# MSS_CTRL_MSS_CTRL register map
Vendor: Texas Instruments
Registers are 32-bit, read-only, reset 0x0 unless marked. A register's access mark holds for its fields unless they carry their own. Offsets are as the file gives them; [hi:lo] are bit positions; 'fields as' and 'values as' point back to an identical list.

## MSS_CTRL_MSS_CTRL (part 4 of 5)
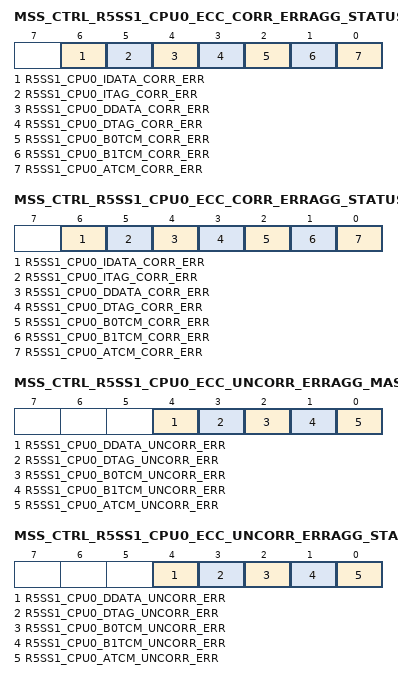
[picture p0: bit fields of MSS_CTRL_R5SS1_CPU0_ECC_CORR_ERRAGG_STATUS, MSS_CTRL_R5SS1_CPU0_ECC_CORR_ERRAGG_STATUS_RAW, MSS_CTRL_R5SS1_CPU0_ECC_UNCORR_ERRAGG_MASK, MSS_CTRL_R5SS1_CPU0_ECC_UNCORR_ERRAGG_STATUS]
0x180C4 MSS_CTRL_R5SS1_CPU0_ECC_CORR_ERRAGG_STATUS 8-bit rw
  [6] R5SS1_CPU0_IDATA_CORR_ERR — Status of Interrupt from correctable error of corresponding CPUSet only if Interupt is unmasked in corresponding R5SS*_CPU*_ECC_CORR_ERRAGG_MASK registerWrie 0x1 to clear this interrupt.
  [5] R5SS1_CPU0_ITAG_CORR_ERR — Status of Interrupt from correctable error of corresponding CPUSet only if Interupt is unmasked in corresponding R5SS*_CPU*_ECC_CORR_ERRAGG_MASK registerWrie 0x1 to clear this interrupt.
  [4] R5SS1_CPU0_DDATA_CORR_ERR — Status of Interrupt from correctable error of corresponding CPUSet only if Interupt is unmasked in corresponding R5SS*_CPU*_ECC_CORR_ERRAGG_MASK registerWrie 0x1 to clear this interrupt.
  [3] R5SS1_CPU0_DTAG_CORR_ERR — Status of Interrupt from correctable error of corresponding CPUSet only if Interupt is unmasked in corresponding R5SS*_CPU*_ECC_CORR_ERRAGG_MASK registerWrie 0x1 to clear this interrupt.
  [2] R5SS1_CPU0_B0TCM_CORR_ERR — Status of Interrupt from correctable error of corresponding CPUSet only if Interupt is unmasked in corresponding R5SS*_CPU*_ECC_CORR_ERRAGG_MASK registerWrie 0x1 to clear this interrupt.
  [1] R5SS1_CPU0_B1TCM_CORR_ERR — Status of Interrupt from correctable error of corresponding CPUSet only if Interupt is unmasked in corresponding R5SS*_CPU*_ECC_CORR_ERRAGG_MASK registerWrie 0x1 to clear this interrupt.
  [0] R5SS1_CPU0_ATCM_CORR_ERR — Status of Interrupt from correctable error of corresponding CPUSet only if Interupt is unmasked in corresponding R5SS*_CPU*_ECC_CORR_ERRAGG_MASK registerWrie 0x1 to clear this interrupt.
0x180C8 MSS_CTRL_R5SS1_CPU0_ECC_CORR_ERRAGG_STATUS_RAW 8-bit rw
  [6] R5SS1_CPU0_IDATA_CORR_ERR — Raw Status of Interrupt from correctable error of corresponding CPUSet only if Interupt is unmasked in corresponding R5SS*_CPU*_ECC_CORR_ERRAGG_MASK registerWrie 0x1 to clear this interrupt.
  [5] R5SS1_CPU0_ITAG_CORR_ERR — Raw Status of Interrupt from correctable error of corresponding CPUSet only if Interupt is unmasked in corresponding R5SS*_CPU*_ECC_CORR_ERRAGG_MASK registerWrie 0x1 to clear this interrupt.
  [4] R5SS1_CPU0_DDATA_CORR_ERR — Raw Status of Interrupt from correctable error of corresponding CPUSet only if Interupt is unmasked in corresponding R5SS*_CPU*_ECC_CORR_ERRAGG_MASK registerWrie 0x1 to clear this interrupt.
  [3] R5SS1_CPU0_DTAG_CORR_ERR — Raw Status of Interrupt from correctable error of corresponding CPUSet only if Interupt is unmasked in corresponding R5SS*_CPU*_ECC_CORR_ERRAGG_MASK registerWrie 0x1 to clear this interrupt.
  [2] R5SS1_CPU0_B0TCM_CORR_ERR — Raw Status of Interrupt from correctable error of corresponding CPUSet only if Interupt is unmasked in corresponding R5SS*_CPU*_ECC_CORR_ERRAGG_MASK registerWrie 0x1 to clear this interrupt.
  [1] R5SS1_CPU0_B1TCM_CORR_ERR — Raw Status of Interrupt from correctable error of corresponding CPUSet only if Interupt is unmasked in corresponding R5SS*_CPU*_ECC_CORR_ERRAGG_MASK registerWrie 0x1 to clear this interrupt.
  [0] R5SS1_CPU0_ATCM_CORR_ERR — Raw Status of Interrupt from correctable error of corresponding CPUSet only if Interupt is unmasked in corresponding R5SS*_CPU*_ECC_CORR_ERRAGG_MASK registerWrie 0x1 to clear this interrupt.
0x180D0 MSS_CTRL_R5SS1_CPU0_ECC_UNCORR_ERRAGG_MASK 8-bit rw
  [4] R5SS1_CPU0_DDATA_UNCORR_ERR — Mask Interrupt for correctable errors to aggregated Interrupt of corresponding CPU1 : Interrupt is Masked0 : Interrupt is Unmasked
  [3] R5SS1_CPU0_DTAG_UNCORR_ERR — Mask Interrupt for correctable errors to aggregated Interrupt of corresponding CPU1 : Interrupt is Masked0 : Interrupt is Unmasked
  [2] R5SS1_CPU0_B0TCM_UNCORR_ERR — Mask Interrupt for correctable errors to aggregated Interrupt of corresponding CPU1 : Interrupt is Masked0 : Interrupt is Unmasked
  [1] R5SS1_CPU0_B1TCM_UNCORR_ERR — Mask Interrupt for correctable errors to aggregated Interrupt of corresponding CPU1 : Interrupt is Masked0 : Interrupt is Unmasked
  [0] R5SS1_CPU0_ATCM_UNCORR_ERR — Mask Interrupt for correctable errors to aggregated Interrupt of corresponding CPU1 : Interrupt is Masked0 : Interrupt is Unmasked
0x180D4 MSS_CTRL_R5SS1_CPU0_ECC_UNCORR_ERRAGG_STATUS 8-bit rw
  [4] R5SS1_CPU0_DDATA_UNCORR_ERR — Status of Interrupt from correctable error of corresponding CPUSet only if Interupt is unmasked in corresponding R5SS*_CPU*_ECC_UNCORR_ERRAGG_MASK registerWrie 0x1 to clear this interrupt.
  [3] R5SS1_CPU0_DTAG_UNCORR_ERR — Status of Interrupt from correctable error of corresponding CPUSet only if Interupt is unmasked in corresponding R5SS*_CPU*_ECC_UNCORR_ERRAGG_MASK registerWrie 0x1 to clear this interrupt.
  [2] R5SS1_CPU0_B0TCM_UNCORR_ERR — Status of Interrupt from correctable error of corresponding CPUSet only if Interupt is unmasked in corresponding R5SS*_CPU*_ECC_UNCORR_ERRAGG_MASK registerWrie 0x1 to clear this interrupt.
  [1] R5SS1_CPU0_B1TCM_UNCORR_ERR — Status of Interrupt from correctable error of corresponding CPUSet only if Interupt is unmasked in corresponding R5SS*_CPU*_ECC_UNCORR_ERRAGG_MASK registerWrie 0x1 to clear this interrupt.
  [0] R5SS1_CPU0_ATCM_UNCORR_ERR — Status of Interrupt from correctable error of corresponding CPUSet only if Interupt is unmasked in corresponding R5SS*_CPU*_ECC_UNCORR_ERRAGG_MASK registerWrie 0x1 to clear this interrupt.
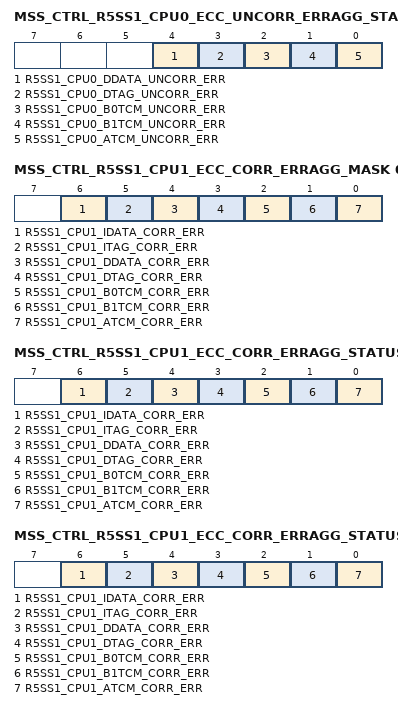
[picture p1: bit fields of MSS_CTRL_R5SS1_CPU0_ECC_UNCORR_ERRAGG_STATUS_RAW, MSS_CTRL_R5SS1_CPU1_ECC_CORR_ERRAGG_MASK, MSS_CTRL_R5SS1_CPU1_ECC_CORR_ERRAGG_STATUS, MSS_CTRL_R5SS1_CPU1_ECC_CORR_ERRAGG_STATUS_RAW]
0x180D8 MSS_CTRL_R5SS1_CPU0_ECC_UNCORR_ERRAGG_STATUS_RAW 8-bit rw
  [4] R5SS1_CPU0_DDATA_UNCORR_ERR — Raw Status of Interrupt from correctable error of corresponding CPUSet only if Interupt is unmasked in corresponding R5SS*_CPU*_ECC_UNCORR_ERRAGG_MASK registerWrie 0x1 to clear this interrupt.
  [3] R5SS1_CPU0_DTAG_UNCORR_ERR — Raw Status of Interrupt from correctable error of corresponding CPUSet only if Interupt is unmasked in corresponding R5SS*_CPU*_ECC_UNCORR_ERRAGG_MASK registerWrie 0x1 to clear this interrupt.
  [2] R5SS1_CPU0_B0TCM_UNCORR_ERR — Raw Status of Interrupt from correctable error of corresponding CPUSet only if Interupt is unmasked in corresponding R5SS*_CPU*_ECC_UNCORR_ERRAGG_MASK registerWrie 0x1 to clear this interrupt.
  [1] R5SS1_CPU0_B1TCM_UNCORR_ERR — Raw Status of Interrupt from correctable error of corresponding CPUSet only if Interupt is unmasked in corresponding R5SS*_CPU*_ECC_UNCORR_ERRAGG_MASK registerWrie 0x1 to clear this interrupt.
  [0] R5SS1_CPU0_ATCM_UNCORR_ERR — Raw Status of Interrupt from correctable error of corresponding CPUSet only if Interupt is unmasked in corresponding R5SS*_CPU*_ECC_UNCORR_ERRAGG_MASK registerWrie 0x1 to clear this interrupt.
0x180E0 MSS_CTRL_R5SS1_CPU1_ECC_CORR_ERRAGG_MASK 8-bit rw
  [6] R5SS1_CPU1_IDATA_CORR_ERR — Mask Interrupt for correctable errors to aggregated Interrupt of corresponding CPU1 : Interrupt is Masked0 : Interrupt is Unmasked
  [5] R5SS1_CPU1_ITAG_CORR_ERR — Mask Interrupt for correctable errors to aggregated Interrupt of corresponding CPU1 : Interrupt is Masked0 : Interrupt is Unmasked
  [4] R5SS1_CPU1_DDATA_CORR_ERR — Mask Interrupt for correctable errors to aggregated Interrupt of corresponding CPU1 : Interrupt is Masked0 : Interrupt is Unmasked
  [3] R5SS1_CPU1_DTAG_CORR_ERR — Mask Interrupt for correctable errors to aggregated Interrupt of corresponding CPU1 : Interrupt is Masked0 : Interrupt is Unmasked
  [2] R5SS1_CPU1_B0TCM_CORR_ERR — Mask Interrupt for correctable errors to aggregated Interrupt of corresponding CPU1 : Interrupt is Masked0 : Interrupt is Unmasked
  [1] R5SS1_CPU1_B1TCM_CORR_ERR — Mask Interrupt for correctable errors to aggregated Interrupt of corresponding CPU1 : Interrupt is Masked0 : Interrupt is Unmasked
  [0] R5SS1_CPU1_ATCM_CORR_ERR — Mask Interrupt for correctable errors to aggregated Interrupt of corresponding CPU1 : Interrupt is Masked0 : Interrupt is Unmasked
0x180E4 MSS_CTRL_R5SS1_CPU1_ECC_CORR_ERRAGG_STATUS 8-bit rw
  [6] R5SS1_CPU1_IDATA_CORR_ERR — Status of Interrupt from correctable error of corresponding CPUSet only if Interupt is unmasked in corresponding R5SS*_CPU*_ECC_CORR_ERRAGG_MASK registerWrie 0x1 to clear this interrupt.
  [5] R5SS1_CPU1_ITAG_CORR_ERR — Status of Interrupt from correctable error of corresponding CPUSet only if Interupt is unmasked in corresponding R5SS*_CPU*_ECC_CORR_ERRAGG_MASK registerWrie 0x1 to clear this interrupt.
  [4] R5SS1_CPU1_DDATA_CORR_ERR — Status of Interrupt from correctable error of corresponding CPUSet only if Interupt is unmasked in corresponding R5SS*_CPU*_ECC_CORR_ERRAGG_MASK registerWrie 0x1 to clear this interrupt.
  [3] R5SS1_CPU1_DTAG_CORR_ERR — Status of Interrupt from correctable error of corresponding CPUSet only if Interupt is unmasked in corresponding R5SS*_CPU*_ECC_CORR_ERRAGG_MASK registerWrie 0x1 to clear this interrupt.
  [2] R5SS1_CPU1_B0TCM_CORR_ERR — Status of Interrupt from correctable error of corresponding CPUSet only if Interupt is unmasked in corresponding R5SS*_CPU*_ECC_CORR_ERRAGG_MASK registerWrie 0x1 to clear this interrupt.
  [1] R5SS1_CPU1_B1TCM_CORR_ERR — Status of Interrupt from correctable error of corresponding CPUSet only if Interupt is unmasked in corresponding R5SS*_CPU*_ECC_CORR_ERRAGG_MASK registerWrie 0x1 to clear this interrupt.
  [0] R5SS1_CPU1_ATCM_CORR_ERR — Status of Interrupt from correctable error of corresponding CPUSet only if Interupt is unmasked in corresponding R5SS*_CPU*_ECC_CORR_ERRAGG_MASK registerWrie 0x1 to clear this interrupt.
0x180E8 MSS_CTRL_R5SS1_CPU1_ECC_CORR_ERRAGG_STATUS_RAW 8-bit rw
  [6] R5SS1_CPU1_IDATA_CORR_ERR — Raw Status of Interrupt from correctable error of corresponding CPUSet only if Interupt is unmasked in corresponding R5SS*_CPU*_ECC_CORR_ERRAGG_MASK registerWrie 0x1 to clear this interrupt.
  [5] R5SS1_CPU1_ITAG_CORR_ERR — Raw Status of Interrupt from correctable error of corresponding CPUSet only if Interupt is unmasked in corresponding R5SS*_CPU*_ECC_CORR_ERRAGG_MASK registerWrie 0x1 to clear this interrupt.
  [4] R5SS1_CPU1_DDATA_CORR_ERR — Raw Status of Interrupt from correctable error of corresponding CPUSet only if Interupt is unmasked in corresponding R5SS*_CPU*_ECC_CORR_ERRAGG_MASK registerWrie 0x1 to clear this interrupt.
  [3] R5SS1_CPU1_DTAG_CORR_ERR — Raw Status of Interrupt from correctable error of corresponding CPUSet only if Interupt is unmasked in corresponding R5SS*_CPU*_ECC_CORR_ERRAGG_MASK registerWrie 0x1 to clear this interrupt.
  [2] R5SS1_CPU1_B0TCM_CORR_ERR — Raw Status of Interrupt from correctable error of corresponding CPUSet only if Interupt is unmasked in corresponding R5SS*_CPU*_ECC_CORR_ERRAGG_MASK registerWrie 0x1 to clear this interrupt.
  [1] R5SS1_CPU1_B1TCM_CORR_ERR — Raw Status of Interrupt from correctable error of corresponding CPUSet only if Interupt is unmasked in corresponding R5SS*_CPU*_ECC_CORR_ERRAGG_MASK registerWrie 0x1 to clear this interrupt.
  [0] R5SS1_CPU1_ATCM_CORR_ERR — Raw Status of Interrupt from correctable error of corresponding CPUSet only if Interupt is unmasked in corresponding R5SS*_CPU*_ECC_CORR_ERRAGG_MASK registerWrie 0x1 to clear this interrupt.
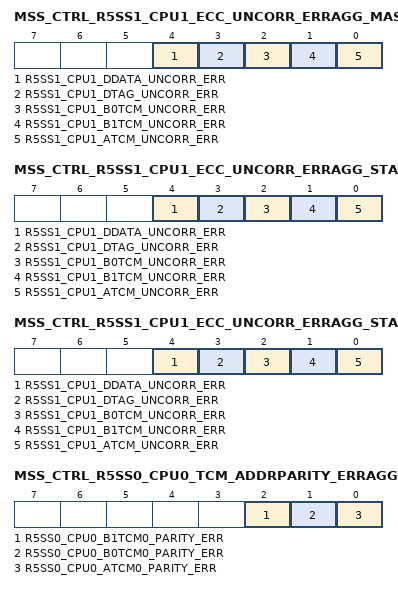
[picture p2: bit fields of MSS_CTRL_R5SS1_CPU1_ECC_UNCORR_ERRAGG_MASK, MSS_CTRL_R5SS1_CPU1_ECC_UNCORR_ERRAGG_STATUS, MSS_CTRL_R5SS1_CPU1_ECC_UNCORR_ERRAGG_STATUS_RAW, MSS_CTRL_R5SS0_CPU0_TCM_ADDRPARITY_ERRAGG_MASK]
0x180F0 MSS_CTRL_R5SS1_CPU1_ECC_UNCORR_ERRAGG_MASK 8-bit rw
  [4] R5SS1_CPU1_DDATA_UNCORR_ERR — Mask Interrupt for correctable errors to aggregated Interrupt of corresponding CPU1 : Interrupt is Masked0 : Interrupt is Unmasked
  [3] R5SS1_CPU1_DTAG_UNCORR_ERR — Mask Interrupt for correctable errors to aggregated Interrupt of corresponding CPU1 : Interrupt is Masked0 : Interrupt is Unmasked
  [2] R5SS1_CPU1_B0TCM_UNCORR_ERR — Mask Interrupt for correctable errors to aggregated Interrupt of corresponding CPU1 : Interrupt is Masked0 : Interrupt is Unmasked
  [1] R5SS1_CPU1_B1TCM_UNCORR_ERR — Mask Interrupt for correctable errors to aggregated Interrupt of corresponding CPU1 : Interrupt is Masked0 : Interrupt is Unmasked
  [0] R5SS1_CPU1_ATCM_UNCORR_ERR — Mask Interrupt for correctable errors to aggregated Interrupt of corresponding CPU1 : Interrupt is Masked0 : Interrupt is Unmasked
0x180F4 MSS_CTRL_R5SS1_CPU1_ECC_UNCORR_ERRAGG_STATUS 8-bit rw
  [4] R5SS1_CPU1_DDATA_UNCORR_ERR — Status of Interrupt from correctable error of corresponding CPUSet only if Interupt is unmasked in corresponding R5SS*_CPU*_ECC_UNCORR_ERRAGG_MASK registerWrie 0x1 to clear this interrupt.
  [3] R5SS1_CPU1_DTAG_UNCORR_ERR — Status of Interrupt from correctable error of corresponding CPUSet only if Interupt is unmasked in corresponding R5SS*_CPU*_ECC_UNCORR_ERRAGG_MASK registerWrie 0x1 to clear this interrupt.
  [2] R5SS1_CPU1_B0TCM_UNCORR_ERR — Status of Interrupt from correctable error of corresponding CPUSet only if Interupt is unmasked in corresponding R5SS*_CPU*_ECC_UNCORR_ERRAGG_MASK registerWrie 0x1 to clear this interrupt.
  [1] R5SS1_CPU1_B1TCM_UNCORR_ERR — Status of Interrupt from correctable error of corresponding CPUSet only if Interupt is unmasked in corresponding R5SS*_CPU*_ECC_UNCORR_ERRAGG_MASK registerWrie 0x1 to clear this interrupt.
  [0] R5SS1_CPU1_ATCM_UNCORR_ERR — Status of Interrupt from correctable error of corresponding CPUSet only if Interupt is unmasked in corresponding R5SS*_CPU*_ECC_UNCORR_ERRAGG_MASK registerWrie 0x1 to clear this interrupt.
0x180F8 MSS_CTRL_R5SS1_CPU1_ECC_UNCORR_ERRAGG_STATUS_RAW 8-bit rw
  [4] R5SS1_CPU1_DDATA_UNCORR_ERR — Raw Status of Interrupt from correctable error of corresponding CPUSet only if Interupt is unmasked in corresponding R5SS*_CPU*_ECC_UNCORR_ERRAGG_MASK registerWrie 0x1 to clear this interrupt.
  [3] R5SS1_CPU1_DTAG_UNCORR_ERR — Raw Status of Interrupt from correctable error of corresponding CPUSet only if Interupt is unmasked in corresponding R5SS*_CPU*_ECC_UNCORR_ERRAGG_MASK registerWrie 0x1 to clear this interrupt.
  [2] R5SS1_CPU1_B0TCM_UNCORR_ERR — Raw Status of Interrupt from correctable error of corresponding CPUSet only if Interupt is unmasked in corresponding R5SS*_CPU*_ECC_UNCORR_ERRAGG_MASK registerWrie 0x1 to clear this interrupt.
  [1] R5SS1_CPU1_B1TCM_UNCORR_ERR — Raw Status of Interrupt from correctable error of corresponding CPUSet only if Interupt is unmasked in corresponding R5SS*_CPU*_ECC_UNCORR_ERRAGG_MASK registerWrie 0x1 to clear this interrupt.
  [0] R5SS1_CPU1_ATCM_UNCORR_ERR — Raw Status of Interrupt from correctable error of corresponding CPUSet only if Interupt is unmasked in corresponding R5SS*_CPU*_ECC_UNCORR_ERRAGG_MASK registerWrie 0x1 to clear this interrupt.
0x18100 MSS_CTRL_R5SS0_CPU0_TCM_ADDRPARITY_ERRAGG_MASK 8-bit rw
  [2] R5SS0_CPU0_B1TCM0_PARITY_ERR — Mask Interrupt for address parity error s to aggregated Interrupt of corresponding CPU1 : Interrupt is Masked0 : Interrupt is Unmasked
  [1] R5SS0_CPU0_B0TCM0_PARITY_ERR — Mask Interrupt for address parity error s to aggregated Interrupt of corresponding CPU1 : Interrupt is Masked0 : Interrupt is Unmasked
  [0] R5SS0_CPU0_ATCM0_PARITY_ERR — Mask Interrupt for address parity error s to aggregated Interrupt of corresponding CPU1 : Interrupt is Masked0 : Interrupt is Unmasked
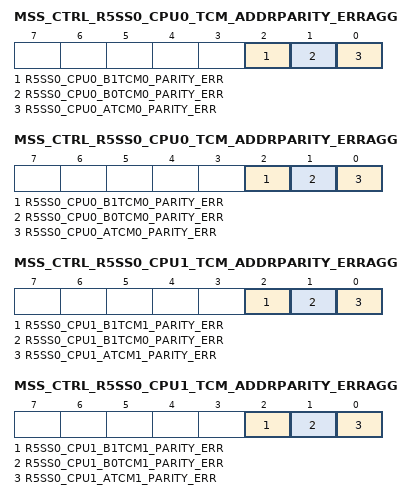
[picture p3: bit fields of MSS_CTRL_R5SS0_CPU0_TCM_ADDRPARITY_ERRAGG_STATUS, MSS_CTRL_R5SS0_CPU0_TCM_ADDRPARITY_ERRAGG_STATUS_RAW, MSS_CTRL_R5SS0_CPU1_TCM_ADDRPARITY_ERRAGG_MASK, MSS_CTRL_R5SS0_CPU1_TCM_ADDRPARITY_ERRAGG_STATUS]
0x18104 MSS_CTRL_R5SS0_CPU0_TCM_ADDRPARITY_ERRAGG_STATUS 8-bit rw
  [2] R5SS0_CPU0_B1TCM0_PARITY_ERR — Status of Interrupt from address parity error of corresponding CPU*_TCM_ADDRPARITY_ERRAGG_MASK registerWrie 0x1 to clear this interrupt.
  [1] R5SS0_CPU0_B0TCM0_PARITY_ERR — Status of Interrupt from address parity error of corresponding CPU*_TCM_ADDRPARITY_ERRAGG_MASK registerWrie 0x1 to clear this interrupt.
  [0] R5SS0_CPU0_ATCM0_PARITY_ERR — Status of Interrupt from address parity error of corresponding CPU*_TCM_ADDRPARITY_ERRAGG_MASK registerWrie 0x1 to clear this interrupt.
0x18108 MSS_CTRL_R5SS0_CPU0_TCM_ADDRPARITY_ERRAGG_STATUS_RAW 8-bit rw
  [2] R5SS0_CPU0_B1TCM0_PARITY_ERR — Raw Status of Interrupt from address parity error of corresponding CPU*_TCM_ADDRPARITY_ERRAGG_MASK registerWrie 0x1 to clear this interrupt.
  [1] R5SS0_CPU0_B0TCM0_PARITY_ERR — Raw Status of Interrupt from address parity error of corresponding CPU*_TCM_ADDRPARITY_ERRAGG_MASK registerWrie 0x1 to clear this interrupt.
  [0] R5SS0_CPU0_ATCM0_PARITY_ERR — Raw Status of Interrupt from address parity error of corresponding CPU*_TCM_ADDRPARITY_ERRAGG_MASK registerWrie 0x1 to clear this interrupt.
0x18110 MSS_CTRL_R5SS0_CPU1_TCM_ADDRPARITY_ERRAGG_MASK 8-bit rw
  [2] R5SS0_CPU1_B1TCM1_PARITY_ERR — Mask Interrupt for address parity error s to aggregated Interrupt of corresponding CPU1 : Interrupt is Masked0 : Interrupt is Unmasked
  [1] R5SS0_CPU1_B1TCM0_PARITY_ERR — Mask Interrupt for address parity error s to aggregated Interrupt of corresponding CPU1 : Interrupt is Masked0 : Interrupt is Unmasked
  [0] R5SS0_CPU1_ATCM1_PARITY_ERR — Mask Interrupt for address parity error s to aggregated Interrupt of corresponding CPU1 : Interrupt is Masked0 : Interrupt is Unmasked
0x18114 MSS_CTRL_R5SS0_CPU1_TCM_ADDRPARITY_ERRAGG_STATUS 8-bit rw
  [2] R5SS0_CPU1_B1TCM1_PARITY_ERR — Status of Interrupt from address parity error of corresponding CPU*_TCM_ADDRPARITY_ERRAGG_MASK registerWrie 0x1 to clear this interrupt.
  [1] R5SS0_CPU1_B0TCM1_PARITY_ERR — Status of Interrupt from address parity error of corresponding CPU*_TCM_ADDRPARITY_ERRAGG_MASK registerWrie 0x1 to clear this interrupt.
  [0] R5SS0_CPU1_ATCM1_PARITY_ERR — Status of Interrupt from address parity error of corresponding CPU*_TCM_ADDRPARITY_ERRAGG_MASK registerWrie 0x1 to clear this interrupt.
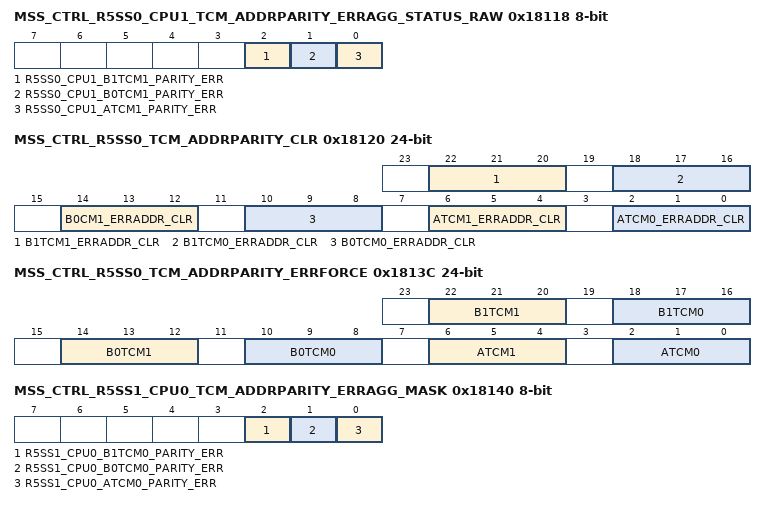
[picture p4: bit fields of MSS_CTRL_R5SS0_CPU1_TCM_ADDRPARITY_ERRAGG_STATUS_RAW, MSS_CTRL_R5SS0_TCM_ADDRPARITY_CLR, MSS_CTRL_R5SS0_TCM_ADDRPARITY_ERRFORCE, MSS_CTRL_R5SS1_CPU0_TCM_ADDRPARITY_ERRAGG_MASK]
0x18118 MSS_CTRL_R5SS0_CPU1_TCM_ADDRPARITY_ERRAGG_STATUS_RAW 8-bit rw
  [2] R5SS0_CPU1_B1TCM1_PARITY_ERR — Raw Status of Interrupt from address parity error of corresponding CPU*_TCM_ADDRPARITY_ERRAGG_MASK registerWrie 0x1 to clear this interrupt.
  [1] R5SS0_CPU1_B0TCM1_PARITY_ERR — Raw Status of Interrupt from address parity error of corresponding CPU*_TCM_ADDRPARITY_ERRAGG_MASK registerWrie 0x1 to clear this interrupt.
  [0] R5SS0_CPU1_ATCM1_PARITY_ERR — Raw Status of Interrupt from address parity error of corresponding CPU*_TCM_ADDRPARITY_ERRAGG_MASK registerWrie 0x1 to clear this interrupt.
0x18120 MSS_CTRL_R5SS0_TCM_ADDRPARITY_CLR 24-bit rw
  [22:20] B1TCM1_ERRADDR_CLR — Write pulse bit field:writing 3'b111 clears the Address latched after parity error for B1TCM of CR5B
  [18:16] B1TCM0_ERRADDR_CLR — Write pulse bit field:writing 3'b111 clears the Address latched after parity error for B1TCM of CR5A
  [14:12] B0CM1_ERRADDR_CLR — Write pulse bit field:writing 3'b111 clears the Address latched after parity error for B0TCM of CR5B
  [10:8] B0TCM0_ERRADDR_CLR — Write pulse bit field:writing 3'b111 clears the Address latched after parity error for B0TCM of CR5A
  [6:4] ATCM1_ERRADDR_CLR — Write pulse bit field:writing 3'b111 clears the Address latched after parity error for ATCM of CR5B
  [2:0] ATCM0_ERRADDR_CLR — Pulse bit-field writing 3'b111 clears the Address latched after parity error for ATCM of CR5A
0x18124 MSS_CTRL_R5SS0_CORE0_ADDRPARITY_ERR_ATCM 24-bit
  [19:0] ADDR — Address lathched when parity error is occurred for ATCM of CR5A
0x18128 MSS_CTRL_R5SS0_CORE1_ADDRPARITY_ERR_ATCM 24-bit
  [19:0] ADDR — Address lathched when parity error is occurred for ATCM of CR5B
0x1812C MSS_CTRL_R5SS0_CORE0_ERR_ADDRPARITY_B0TCM 24-bit
  [19:0] ADDR — Address lathched when parity error is occurred for B0TCM of CR5A
0x18130 MSS_CTRL_R5SS0_CORE1_ERR_ADDRPARITY_B0TCM 24-bit
  [19:0] ADDR — Address lathched when parity error is occurred for B0TCM of CR5B
0x18134 MSS_CTRL_R5SS0_CORE0_ERR_ADDRPARITY_B1TCM 24-bit
  [19:0] ADDR — Address lathched when parity error is occurred for B1TCM of CR5A
0x18138 MSS_CTRL_R5SS0_CORE1_ERR_ADDRPARITY_B1TCM 24-bit
  [19:0] ADDR — Address lathched when parity error is occurred for B1TCM of CR5B
0x1813C MSS_CTRL_R5SS0_TCM_ADDRPARITY_ERRFORCE 24-bit rw
  [22:20] B1TCM1 — Write pulse bit field:writing 3'b111 forces a parity error for B1TCM of CR5B
  [18:16] B1TCM0 — Write pulse bit field:writing 3'b111 forces a parity error for B1TCM of CR5A
  [14:12] B0TCM1 — Write pulse bit field:writing 3'b111 forces a parity error for B0TCM of CR5B
  [10:8] B0TCM0 — Write pulse bit field:writing 3'b111 forces a parity error for B0TCM of CR5A
  [6:4] ATCM1 — Write pulse bit field:writing 3'b111 forces a parity error for ATCM of CR5B
  [2:0] ATCM0 — Write pulse bit field:writing 3'b111 forces a parity error for ATCM of CR5A
0x18140 MSS_CTRL_R5SS1_CPU0_TCM_ADDRPARITY_ERRAGG_MASK 8-bit rw
  [2] R5SS1_CPU0_B1TCM0_PARITY_ERR — Mask Interrupt for address parity error s to aggregated Interrupt of corresponding CPU1 : Interrupt is Masked0 : Interrupt is Unmasked
  [1] R5SS1_CPU0_B0TCM0_PARITY_ERR — Mask Interrupt for address parity error s to aggregated Interrupt of corresponding CPU1 : Interrupt is Masked0 : Interrupt is Unmasked
  [0] R5SS1_CPU0_ATCM0_PARITY_ERR — Mask Interrupt for address parity error s to aggregated Interrupt of corresponding CPU1 : Interrupt is Masked0 : Interrupt is Unmasked
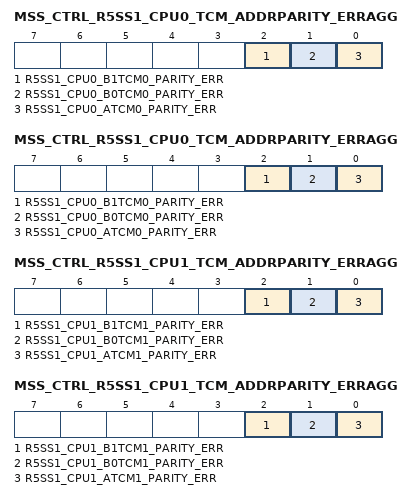
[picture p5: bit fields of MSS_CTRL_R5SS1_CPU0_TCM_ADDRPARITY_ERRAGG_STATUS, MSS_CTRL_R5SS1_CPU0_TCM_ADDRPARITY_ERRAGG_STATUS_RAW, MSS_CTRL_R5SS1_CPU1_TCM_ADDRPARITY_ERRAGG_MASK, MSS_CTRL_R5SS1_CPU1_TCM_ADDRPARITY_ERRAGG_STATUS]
0x18144 MSS_CTRL_R5SS1_CPU0_TCM_ADDRPARITY_ERRAGG_STATUS 8-bit rw
  [2] R5SS1_CPU0_B1TCM0_PARITY_ERR — Status of Interrupt from address parity error of corresponding CPU*_TCM_ADDRPARITY_ERRAGG_MASK registerWrie 0x1 to clear this interrupt.
  [1] R5SS1_CPU0_B0TCM0_PARITY_ERR — Status of Interrupt from address parity error of corresponding CPU*_TCM_ADDRPARITY_ERRAGG_MASK registerWrie 0x1 to clear this interrupt.
  [0] R5SS1_CPU0_ATCM0_PARITY_ERR — Status of Interrupt from address parity error of corresponding CPU*_TCM_ADDRPARITY_ERRAGG_MASK registerWrie 0x1 to clear this interrupt.
0x18148 MSS_CTRL_R5SS1_CPU0_TCM_ADDRPARITY_ERRAGG_STATUS_RAW 8-bit rw
  [2] R5SS1_CPU0_B1TCM0_PARITY_ERR — Raw Status of Interrupt from address parity error of corresponding CPU*_TCM_ADDRPARITY_ERRAGG_MASK registerWrie 0x1 to clear this interrupt.
  [1] R5SS1_CPU0_B0TCM0_PARITY_ERR — Raw Status of Interrupt from address parity error of corresponding CPU*_TCM_ADDRPARITY_ERRAGG_MASK registerWrie 0x1 to clear this interrupt.
  [0] R5SS1_CPU0_ATCM0_PARITY_ERR — Raw Status of Interrupt from address parity error of corresponding CPU*_TCM_ADDRPARITY_ERRAGG_MASK registerWrie 0x1 to clear this interrupt.
0x18150 MSS_CTRL_R5SS1_CPU1_TCM_ADDRPARITY_ERRAGG_MASK 8-bit rw
  [2] R5SS1_CPU1_B1TCM1_PARITY_ERR — Mask Interrupt for address parity error s to aggregated Interrupt of corresponding CPU1 : Interrupt is Masked0 : Interrupt is Unmasked
  [1] R5SS1_CPU1_B0TCM1_PARITY_ERR — Mask Interrupt for address parity error s to aggregated Interrupt of corresponding CPU1 : Interrupt is Masked0 : Interrupt is Unmasked
  [0] R5SS1_CPU1_ATCM1_PARITY_ERR — Mask Interrupt for address parity error s to aggregated Interrupt of corresponding CPU1 : Interrupt is Masked0 : Interrupt is Unmasked
0x18154 MSS_CTRL_R5SS1_CPU1_TCM_ADDRPARITY_ERRAGG_STATUS 8-bit rw
  [2] R5SS1_CPU1_B1TCM1_PARITY_ERR — Status of Interrupt from address parity error of corresponding CPU*_TCM_ADDRPARITY_ERRAGG_MASK registerWrie 0x1 to clear this interrupt.
  [1] R5SS1_CPU1_B0TCM1_PARITY_ERR — Status of Interrupt from address parity error of corresponding CPU*_TCM_ADDRPARITY_ERRAGG_MASK registerWrie 0x1 to clear this interrupt.
  [0] R5SS1_CPU1_ATCM1_PARITY_ERR — Status of Interrupt from address parity error of corresponding CPU*_TCM_ADDRPARITY_ERRAGG_MASK registerWrie 0x1 to clear this interrupt.
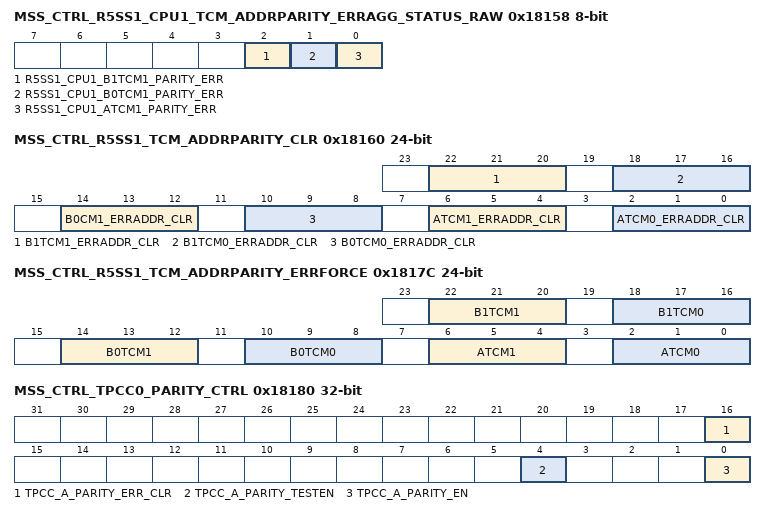
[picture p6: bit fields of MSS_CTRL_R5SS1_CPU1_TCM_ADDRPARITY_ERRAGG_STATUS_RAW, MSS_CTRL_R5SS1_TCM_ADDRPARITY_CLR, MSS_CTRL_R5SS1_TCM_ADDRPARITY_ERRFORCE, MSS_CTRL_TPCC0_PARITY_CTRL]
0x18158 MSS_CTRL_R5SS1_CPU1_TCM_ADDRPARITY_ERRAGG_STATUS_RAW 8-bit rw
  [2] R5SS1_CPU1_B1TCM1_PARITY_ERR — Raw Status of Interrupt from address parity error of corresponding CPU*_TCM_ADDRPARITY_ERRAGG_MASK registerWrie 0x1 to clear this interrupt.
  [1] R5SS1_CPU1_B0TCM1_PARITY_ERR — Raw Status of Interrupt from address parity error of corresponding CPU*_TCM_ADDRPARITY_ERRAGG_MASK registerWrie 0x1 to clear this interrupt.
  [0] R5SS1_CPU1_ATCM1_PARITY_ERR — Raw Status of Interrupt from address parity error of corresponding CPU*_TCM_ADDRPARITY_ERRAGG_MASK registerWrie 0x1 to clear this interrupt.
0x18160 MSS_CTRL_R5SS1_TCM_ADDRPARITY_CLR 24-bit rw
  fields as MSS_CTRL_R5SS0_TCM_ADDRPARITY_CLR
0x18164 MSS_CTRL_R5SS1_CORE0_ADDRPARITY_ERR_ATCM 24-bit
  fields as MSS_CTRL_R5SS0_CORE0_ADDRPARITY_ERR_ATCM
0x18168 MSS_CTRL_R5SS1_CORE1_ADDRPARITY_ERR_ATCM 24-bit
  fields as MSS_CTRL_R5SS0_CORE1_ADDRPARITY_ERR_ATCM
0x1816C MSS_CTRL_R5SS1_CORE0_ERR_ADDRPARITY_B0TCM 24-bit
  fields as MSS_CTRL_R5SS0_CORE0_ERR_ADDRPARITY_B0TCM
0x18170 MSS_CTRL_R5SS1_CORE1_ERR_ADDRPARITY_B0TCM 24-bit
  fields as MSS_CTRL_R5SS0_CORE1_ERR_ADDRPARITY_B0TCM
0x18174 MSS_CTRL_R5SS1_CORE0_ERR_ADDRPARITY_B1TCM 24-bit
  fields as MSS_CTRL_R5SS0_CORE0_ERR_ADDRPARITY_B1TCM
0x18178 MSS_CTRL_R5SS1_CORE1_ERR_ADDRPARITY_B1TCM 24-bit
  fields as MSS_CTRL_R5SS0_CORE1_ERR_ADDRPARITY_B1TCM
0x1817C MSS_CTRL_R5SS1_TCM_ADDRPARITY_ERRFORCE 24-bit rw
  fields as MSS_CTRL_R5SS0_TCM_ADDRPARITY_ERRFORCE
0x18180 MSS_CTRL_TPCC0_PARITY_CTRL rw
  [16] TPCC_A_PARITY_ERR_CLR — Write pulse bit field:parity clear bit. Writing 1'b1 will clear the tpcc_a_parity_addr
  [4] TPCC_A_PARITY_TESTEN — parity test enable for tpcc a
  [0] TPCC_A_PARITY_EN — writing 1'b1 enables parity for TPCC_A
0x18184 MSS_CTRL_TPCC0_PARITY_STATUS 16-bit
  [8:0] TPCC_A_PARITY_ADDR — address where parity error happened for tpcca
0x18200 MSS_CTRL_BUS_SAFETY_CTRL 8-bit rw
  [2:0] ENABLE — Refer to AM602 Substem Microarch document for more details
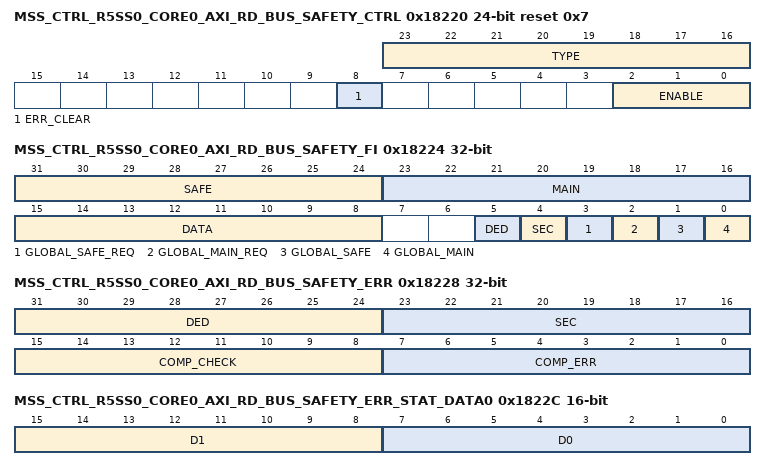
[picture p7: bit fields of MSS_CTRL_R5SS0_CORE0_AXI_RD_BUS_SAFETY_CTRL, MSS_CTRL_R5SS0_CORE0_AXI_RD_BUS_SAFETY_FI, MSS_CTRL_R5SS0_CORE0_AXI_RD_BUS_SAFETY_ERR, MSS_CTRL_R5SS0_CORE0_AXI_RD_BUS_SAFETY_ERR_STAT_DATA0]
0x18220 MSS_CTRL_R5SS0_CORE0_AXI_RD_BUS_SAFETY_CTRL 24-bit access per field reset 0x7
  [23:16] TYPE ro — Refer to AM602 Substem Microarch document for more details
  [8] ERR_CLEAR rw — Refer to AM602 Substem Microarch document for more details
  [2:0] ENABLE rw — Refer to AM602 Substem Microarch document for more details
0x18224 MSS_CTRL_R5SS0_CORE0_AXI_RD_BUS_SAFETY_FI rw
  [31:24] SAFE — Refer to AM602 Substem Microarch document for more details
  [23:16] MAIN — Refer to AM602 Substem Microarch document for more details
  [15:8] DATA — Refer to AM602 Substem Microarch document for more details
  [5] DED — Refer to AM602 Substem Microarch document for more details
  [4] SEC — Refer to AM602 Substem Microarch document for more details
  [3] GLOBAL_SAFE_REQ — Refer to AM602 Substem Microarch document for more details
  [2] GLOBAL_MAIN_REQ — Refer to AM602 Substem Microarch document for more details
  [1] GLOBAL_SAFE — Refer to AM602 Substem Microarch document for more details
  [0] GLOBAL_MAIN — Refer to AM602 Substem Microarch document for more details
0x18228 MSS_CTRL_R5SS0_CORE0_AXI_RD_BUS_SAFETY_ERR
  [31:24] DED — Refer to AM602 Substem Microarch document for more details
  [23:16] SEC — Refer to AM602 Substem Microarch document for more details
  [15:8] COMP_CHECK — Refer to AM602 Substem Microarch document for more details
  [7:0] COMP_ERR — Refer to AM602 Substem Microarch document for more details
0x1822C MSS_CTRL_R5SS0_CORE0_AXI_RD_BUS_SAFETY_ERR_STAT_DATA0 16-bit
  [15:8] D1 — Refer to AM602 Substem Microarch document for more details
  [7:0] D0 — Refer to AM602 Substem Microarch document for more details
0x18230 MSS_CTRL_R5SS0_CORE0_AXI_RD_BUS_SAFETY_ERR_STAT_CMD
  [31:0] STAT — Refer to AM602 Substem Microarch document for more details
0x18234 MSS_CTRL_R5SS0_CORE0_AXI_RD_BUS_SAFETY_ERR_STAT_READ
  fields as MSS_CTRL_R5SS0_CORE0_AXI_RD_BUS_SAFETY_ERR_STAT_CMD
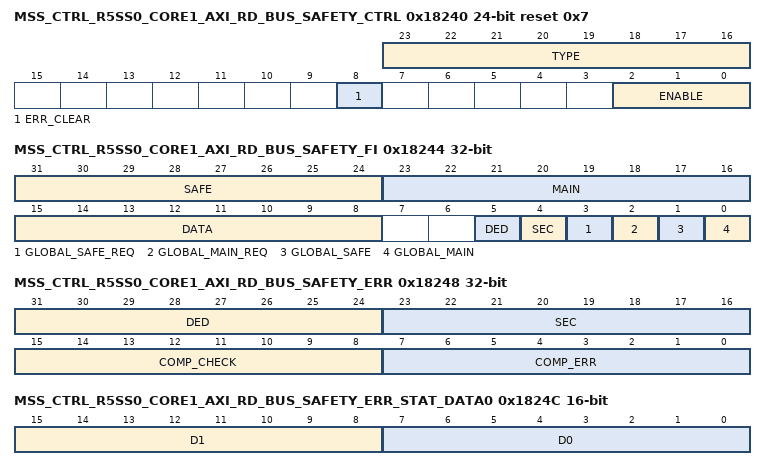
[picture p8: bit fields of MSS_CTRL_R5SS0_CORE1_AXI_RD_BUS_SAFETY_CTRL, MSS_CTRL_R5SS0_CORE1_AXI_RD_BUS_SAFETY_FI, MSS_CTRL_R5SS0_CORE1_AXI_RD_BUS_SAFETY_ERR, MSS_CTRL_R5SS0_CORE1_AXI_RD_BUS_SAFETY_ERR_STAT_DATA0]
0x18240 MSS_CTRL_R5SS0_CORE1_AXI_RD_BUS_SAFETY_CTRL 24-bit access per field reset 0x7
  fields as MSS_CTRL_R5SS0_CORE0_AXI_RD_BUS_SAFETY_CTRL
0x18244 MSS_CTRL_R5SS0_CORE1_AXI_RD_BUS_SAFETY_FI rw
  fields as MSS_CTRL_R5SS0_CORE0_AXI_RD_BUS_SAFETY_FI
0x18248 MSS_CTRL_R5SS0_CORE1_AXI_RD_BUS_SAFETY_ERR
  fields as MSS_CTRL_R5SS0_CORE0_AXI_RD_BUS_SAFETY_ERR
0x1824C MSS_CTRL_R5SS0_CORE1_AXI_RD_BUS_SAFETY_ERR_STAT_DATA0 16-bit
  fields as MSS_CTRL_R5SS0_CORE0_AXI_RD_BUS_SAFETY_ERR_STAT_DATA0
0x18250 MSS_CTRL_R5SS0_CORE1_AXI_RD_BUS_SAFETY_ERR_STAT_CMD
  fields as MSS_CTRL_R5SS0_CORE0_AXI_RD_BUS_SAFETY_ERR_STAT_CMD
0x18254 MSS_CTRL_R5SS0_CORE1_AXI_RD_BUS_SAFETY_ERR_STAT_READ
  fields as MSS_CTRL_R5SS0_CORE0_AXI_RD_BUS_SAFETY_ERR_STAT_CMD
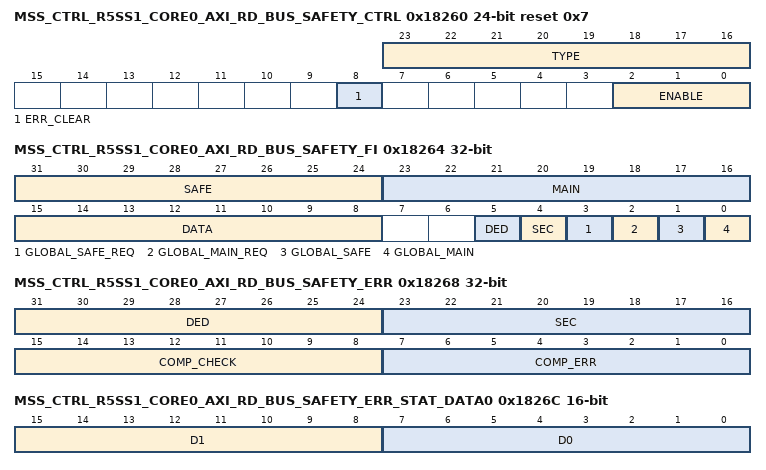
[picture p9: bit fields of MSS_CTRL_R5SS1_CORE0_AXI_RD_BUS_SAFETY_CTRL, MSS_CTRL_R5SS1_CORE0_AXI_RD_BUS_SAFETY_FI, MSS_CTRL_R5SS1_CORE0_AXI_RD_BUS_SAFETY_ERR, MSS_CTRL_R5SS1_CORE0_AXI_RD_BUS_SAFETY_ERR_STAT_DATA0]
0x18260 MSS_CTRL_R5SS1_CORE0_AXI_RD_BUS_SAFETY_CTRL 24-bit access per field reset 0x7
  fields as MSS_CTRL_R5SS0_CORE0_AXI_RD_BUS_SAFETY_CTRL
0x18264 MSS_CTRL_R5SS1_CORE0_AXI_RD_BUS_SAFETY_FI rw
  fields as MSS_CTRL_R5SS0_CORE0_AXI_RD_BUS_SAFETY_FI
0x18268 MSS_CTRL_R5SS1_CORE0_AXI_RD_BUS_SAFETY_ERR
  fields as MSS_CTRL_R5SS0_CORE0_AXI_RD_BUS_SAFETY_ERR
0x1826C MSS_CTRL_R5SS1_CORE0_AXI_RD_BUS_SAFETY_ERR_STAT_DATA0 16-bit
  fields as MSS_CTRL_R5SS0_CORE0_AXI_RD_BUS_SAFETY_ERR_STAT_DATA0
0x18270 MSS_CTRL_R5SS1_CORE0_AXI_RD_BUS_SAFETY_ERR_STAT_CMD
  fields as MSS_CTRL_R5SS0_CORE0_AXI_RD_BUS_SAFETY_ERR_STAT_CMD
0x18274 MSS_CTRL_R5SS1_CORE0_AXI_RD_BUS_SAFETY_ERR_STAT_READ
  fields as MSS_CTRL_R5SS0_CORE0_AXI_RD_BUS_SAFETY_ERR_STAT_CMD
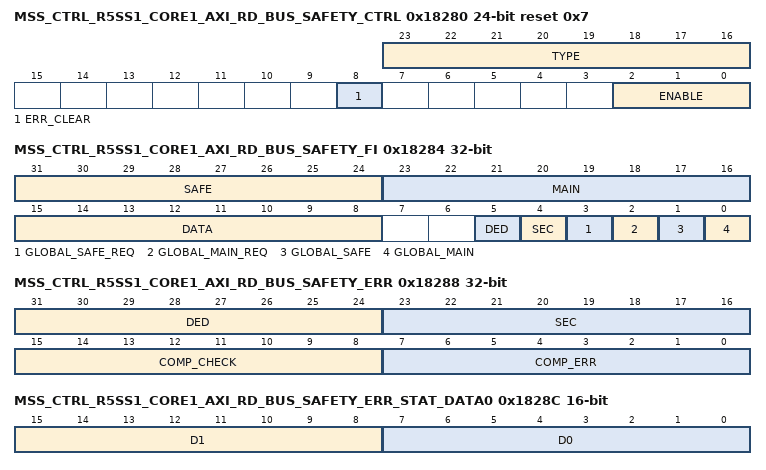
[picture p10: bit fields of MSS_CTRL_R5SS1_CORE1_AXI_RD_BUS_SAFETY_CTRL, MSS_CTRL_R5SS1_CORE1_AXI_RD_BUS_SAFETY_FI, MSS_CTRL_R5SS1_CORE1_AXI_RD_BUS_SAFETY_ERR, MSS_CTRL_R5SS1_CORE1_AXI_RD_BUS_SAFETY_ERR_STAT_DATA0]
0x18280 MSS_CTRL_R5SS1_CORE1_AXI_RD_BUS_SAFETY_CTRL 24-bit access per field reset 0x7
  fields as MSS_CTRL_R5SS0_CORE0_AXI_RD_BUS_SAFETY_CTRL
0x18284 MSS_CTRL_R5SS1_CORE1_AXI_RD_BUS_SAFETY_FI rw
  fields as MSS_CTRL_R5SS0_CORE0_AXI_RD_BUS_SAFETY_FI
0x18288 MSS_CTRL_R5SS1_CORE1_AXI_RD_BUS_SAFETY_ERR
  fields as MSS_CTRL_R5SS0_CORE0_AXI_RD_BUS_SAFETY_ERR
0x1828C MSS_CTRL_R5SS1_CORE1_AXI_RD_BUS_SAFETY_ERR_STAT_DATA0 16-bit
  fields as MSS_CTRL_R5SS0_CORE0_AXI_RD_BUS_SAFETY_ERR_STAT_DATA0
0x18290 MSS_CTRL_R5SS1_CORE1_AXI_RD_BUS_SAFETY_ERR_STAT_CMD
  fields as MSS_CTRL_R5SS0_CORE0_AXI_RD_BUS_SAFETY_ERR_STAT_CMD
0x18294 MSS_CTRL_R5SS1_CORE1_AXI_RD_BUS_SAFETY_ERR_STAT_READ
  fields as MSS_CTRL_R5SS0_CORE0_AXI_RD_BUS_SAFETY_ERR_STAT_CMD
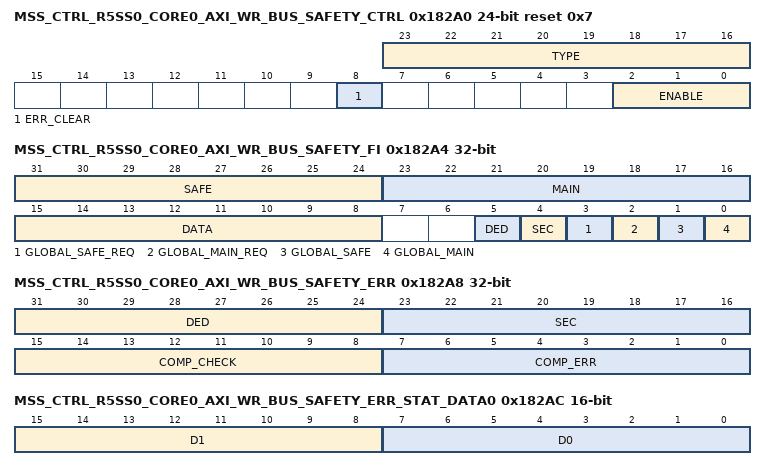
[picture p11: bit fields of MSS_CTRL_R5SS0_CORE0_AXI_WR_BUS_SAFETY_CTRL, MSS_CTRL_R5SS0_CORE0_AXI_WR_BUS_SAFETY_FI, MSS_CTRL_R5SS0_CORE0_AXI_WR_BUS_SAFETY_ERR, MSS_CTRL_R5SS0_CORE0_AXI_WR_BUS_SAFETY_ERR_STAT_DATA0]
0x182A0 MSS_CTRL_R5SS0_CORE0_AXI_WR_BUS_SAFETY_CTRL 24-bit access per field reset 0x7
  fields as MSS_CTRL_R5SS0_CORE0_AXI_RD_BUS_SAFETY_CTRL
0x182A4 MSS_CTRL_R5SS0_CORE0_AXI_WR_BUS_SAFETY_FI rw
  fields as MSS_CTRL_R5SS0_CORE0_AXI_RD_BUS_SAFETY_FI
0x182A8 MSS_CTRL_R5SS0_CORE0_AXI_WR_BUS_SAFETY_ERR
  fields as MSS_CTRL_R5SS0_CORE0_AXI_RD_BUS_SAFETY_ERR
0x182AC MSS_CTRL_R5SS0_CORE0_AXI_WR_BUS_SAFETY_ERR_STAT_DATA0 16-bit
  fields as MSS_CTRL_R5SS0_CORE0_AXI_RD_BUS_SAFETY_ERR_STAT_DATA0
0x182B0 MSS_CTRL_R5SS0_CORE0_AXI_WR_BUS_SAFETY_ERR_STAT_CMD
  fields as MSS_CTRL_R5SS0_CORE0_AXI_RD_BUS_SAFETY_ERR_STAT_CMD
0x182B4 MSS_CTRL_R5SS0_CORE0_AXI_WR_BUS_SAFETY_ERR_STAT_WRITE
  fields as MSS_CTRL_R5SS0_CORE0_AXI_RD_BUS_SAFETY_ERR_STAT_CMD
0x182B8 MSS_CTRL_R5SS0_CORE0_AXI_WR_BUS_SAFETY_ERR_STAT_WRITERESP
  fields as MSS_CTRL_R5SS0_CORE0_AXI_RD_BUS_SAFETY_ERR_STAT_CMD
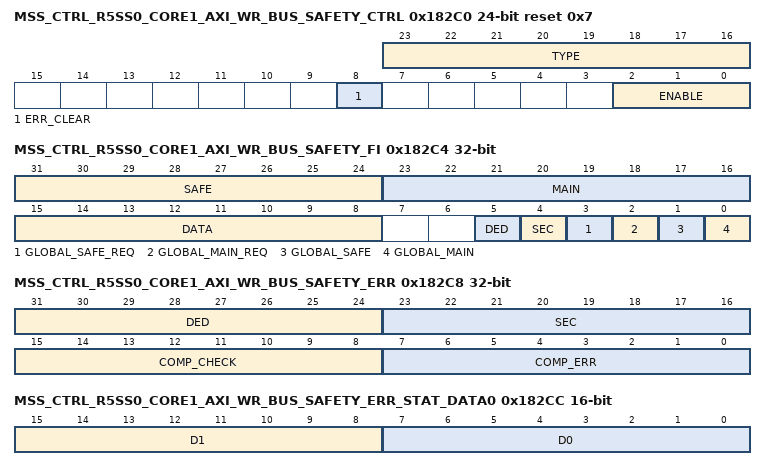
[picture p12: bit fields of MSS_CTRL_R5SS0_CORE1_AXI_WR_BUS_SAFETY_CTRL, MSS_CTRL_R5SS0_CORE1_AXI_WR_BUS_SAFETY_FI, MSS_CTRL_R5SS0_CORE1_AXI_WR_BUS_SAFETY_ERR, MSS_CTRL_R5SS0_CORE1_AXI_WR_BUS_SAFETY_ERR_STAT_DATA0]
0x182C0 MSS_CTRL_R5SS0_CORE1_AXI_WR_BUS_SAFETY_CTRL 24-bit access per field reset 0x7
  fields as MSS_CTRL_R5SS0_CORE0_AXI_RD_BUS_SAFETY_CTRL
0x182C4 MSS_CTRL_R5SS0_CORE1_AXI_WR_BUS_SAFETY_FI rw
  fields as MSS_CTRL_R5SS0_CORE0_AXI_RD_BUS_SAFETY_FI
0x182C8 MSS_CTRL_R5SS0_CORE1_AXI_WR_BUS_SAFETY_ERR
  fields as MSS_CTRL_R5SS0_CORE0_AXI_RD_BUS_SAFETY_ERR
0x182CC MSS_CTRL_R5SS0_CORE1_AXI_WR_BUS_SAFETY_ERR_STAT_DATA0 16-bit
  fields as MSS_CTRL_R5SS0_CORE0_AXI_RD_BUS_SAFETY_ERR_STAT_DATA0
0x182D0 MSS_CTRL_R5SS0_CORE1_AXI_WR_BUS_SAFETY_ERR_STAT_CMD
  fields as MSS_CTRL_R5SS0_CORE0_AXI_RD_BUS_SAFETY_ERR_STAT_CMD
0x182D4 MSS_CTRL_R5SS0_CORE1_AXI_WR_BUS_SAFETY_ERR_STAT_WRITE
  fields as MSS_CTRL_R5SS0_CORE0_AXI_RD_BUS_SAFETY_ERR_STAT_CMD
0x182D8 MSS_CTRL_R5SS0_CORE1_AXI_WR_BUS_SAFETY_ERR_STAT_WRITERESP
  fields as MSS_CTRL_R5SS0_CORE0_AXI_RD_BUS_SAFETY_ERR_STAT_CMD
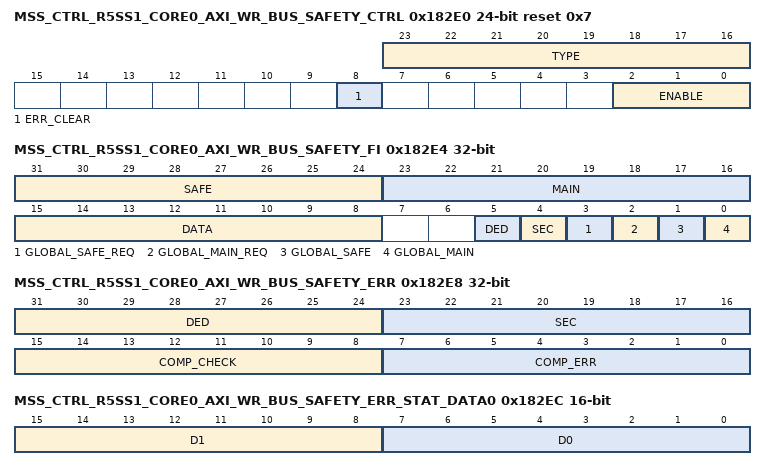
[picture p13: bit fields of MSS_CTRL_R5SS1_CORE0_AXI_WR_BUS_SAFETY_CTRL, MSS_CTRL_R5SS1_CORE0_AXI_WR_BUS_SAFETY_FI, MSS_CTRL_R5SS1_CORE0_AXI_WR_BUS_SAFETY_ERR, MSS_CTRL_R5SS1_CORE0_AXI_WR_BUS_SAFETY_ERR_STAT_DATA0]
0x182E0 MSS_CTRL_R5SS1_CORE0_AXI_WR_BUS_SAFETY_CTRL 24-bit access per field reset 0x7
  fields as MSS_CTRL_R5SS0_CORE0_AXI_RD_BUS_SAFETY_CTRL
0x182E4 MSS_CTRL_R5SS1_CORE0_AXI_WR_BUS_SAFETY_FI rw
  fields as MSS_CTRL_R5SS0_CORE0_AXI_RD_BUS_SAFETY_FI
0x182E8 MSS_CTRL_R5SS1_CORE0_AXI_WR_BUS_SAFETY_ERR
  fields as MSS_CTRL_R5SS0_CORE0_AXI_RD_BUS_SAFETY_ERR
0x182EC MSS_CTRL_R5SS1_CORE0_AXI_WR_BUS_SAFETY_ERR_STAT_DATA0 16-bit
  fields as MSS_CTRL_R5SS0_CORE0_AXI_RD_BUS_SAFETY_ERR_STAT_DATA0
0x182F0 MSS_CTRL_R5SS1_CORE0_AXI_WR_BUS_SAFETY_ERR_STAT_CMD
  fields as MSS_CTRL_R5SS0_CORE0_AXI_RD_BUS_SAFETY_ERR_STAT_CMD
0x182F4 MSS_CTRL_R5SS1_CORE0_AXI_WR_BUS_SAFETY_ERR_STAT_WRITE
  fields as MSS_CTRL_R5SS0_CORE0_AXI_RD_BUS_SAFETY_ERR_STAT_CMD
0x182F8 MSS_CTRL_R5SS1_CORE0_AXI_WR_BUS_SAFETY_ERR_STAT_WRITERESP
  fields as MSS_CTRL_R5SS0_CORE0_AXI_RD_BUS_SAFETY_ERR_STAT_CMD
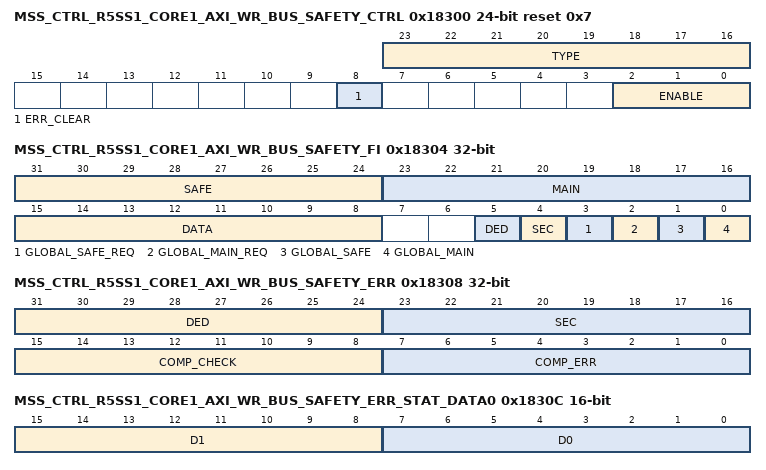
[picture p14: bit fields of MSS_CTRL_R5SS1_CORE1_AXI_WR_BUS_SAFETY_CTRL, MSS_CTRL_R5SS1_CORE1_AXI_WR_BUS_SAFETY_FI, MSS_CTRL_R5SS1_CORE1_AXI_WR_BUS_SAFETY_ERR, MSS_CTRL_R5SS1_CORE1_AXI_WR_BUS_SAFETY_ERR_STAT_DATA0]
0x18300 MSS_CTRL_R5SS1_CORE1_AXI_WR_BUS_SAFETY_CTRL 24-bit access per field reset 0x7
  fields as MSS_CTRL_R5SS0_CORE0_AXI_RD_BUS_SAFETY_CTRL
0x18304 MSS_CTRL_R5SS1_CORE1_AXI_WR_BUS_SAFETY_FI rw
  fields as MSS_CTRL_R5SS0_CORE0_AXI_RD_BUS_SAFETY_FI
0x18308 MSS_CTRL_R5SS1_CORE1_AXI_WR_BUS_SAFETY_ERR
  fields as MSS_CTRL_R5SS0_CORE0_AXI_RD_BUS_SAFETY_ERR
0x1830C MSS_CTRL_R5SS1_CORE1_AXI_WR_BUS_SAFETY_ERR_STAT_DATA0 16-bit
  fields as MSS_CTRL_R5SS0_CORE0_AXI_RD_BUS_SAFETY_ERR_STAT_DATA0
0x18310 MSS_CTRL_R5SS1_CORE1_AXI_WR_BUS_SAFETY_ERR_STAT_CMD
  fields as MSS_CTRL_R5SS0_CORE0_AXI_RD_BUS_SAFETY_ERR_STAT_CMD
0x18314 MSS_CTRL_R5SS1_CORE1_AXI_WR_BUS_SAFETY_ERR_STAT_WRITE
  fields as MSS_CTRL_R5SS0_CORE0_AXI_RD_BUS_SAFETY_ERR_STAT_CMD
0x18318 MSS_CTRL_R5SS1_CORE1_AXI_WR_BUS_SAFETY_ERR_STAT_WRITERESP
  fields as MSS_CTRL_R5SS0_CORE0_AXI_RD_BUS_SAFETY_ERR_STAT_CMD
0x18320 MSS_CTRL_R5SS0_CORE0_AXI_S_BUS_SAFETY_CTRL 24-bit access per field reset 0x7
  fields as MSS_CTRL_R5SS0_CORE0_AXI_RD_BUS_SAFETY_CTRL
0x18324 MSS_CTRL_R5SS0_CORE0_AXI_S_BUS_SAFETY_FI rw
  fields as MSS_CTRL_R5SS0_CORE0_AXI_RD_BUS_SAFETY_FI
0x18328 MSS_CTRL_R5SS0_CORE0_AXI_S_BUS_SAFETY_ERR
  fields as MSS_CTRL_R5SS0_CORE0_AXI_RD_BUS_SAFETY_ERR
0x1832C MSS_CTRL_R5SS0_CORE0_AXI_S_BUS_SAFETY_ERR_STAT_DATA0 16-bit
  fields as MSS_CTRL_R5SS0_CORE0_AXI_RD_BUS_SAFETY_ERR_STAT_DATA0
0x18330 MSS_CTRL_R5SS0_CORE0_AXI_S_BUS_SAFETY_ERR_STAT_CMD
  fields as MSS_CTRL_R5SS0_CORE0_AXI_RD_BUS_SAFETY_ERR_STAT_CMD
0x18334 MSS_CTRL_R5SS0_CORE0_AXI_S_BUS_SAFETY_ERR_STAT_WRITE
  fields as MSS_CTRL_R5SS0_CORE0_AXI_RD_BUS_SAFETY_ERR_STAT_CMD
0x18338 MSS_CTRL_R5SS0_CORE0_AXI_S_BUS_SAFETY_ERR_STAT_READ
  fields as MSS_CTRL_R5SS0_CORE0_AXI_RD_BUS_SAFETY_ERR_STAT_CMD
0x1833C MSS_CTRL_R5SS0_CORE0_AXI_S_BUS_SAFETY_ERR_STAT_WRITERESP
  fields as MSS_CTRL_R5SS0_CORE0_AXI_RD_BUS_SAFETY_ERR_STAT_CMD
0x18340 MSS_CTRL_R5SS0_CORE1_AXI_S_BUS_SAFETY_CTRL 24-bit access per field reset 0x7
  fields as MSS_CTRL_R5SS0_CORE0_AXI_RD_BUS_SAFETY_CTRL
0x18344 MSS_CTRL_R5SS0_CORE1_AXI_S_BUS_SAFETY_FI rw
  fields as MSS_CTRL_R5SS0_CORE0_AXI_RD_BUS_SAFETY_FI
0x18348 MSS_CTRL_R5SS0_CORE1_AXI_S_BUS_SAFETY_ERR
  fields as MSS_CTRL_R5SS0_CORE0_AXI_RD_BUS_SAFETY_ERR
0x1834C MSS_CTRL_R5SS0_CORE1_AXI_S_BUS_SAFETY_ERR_STAT_DATA0 16-bit
  fields as MSS_CTRL_R5SS0_CORE0_AXI_RD_BUS_SAFETY_ERR_STAT_DATA0
0x18350 MSS_CTRL_R5SS0_CORE1_AXI_S_BUS_SAFETY_ERR_STAT_CMD
  fields as MSS_CTRL_R5SS0_CORE0_AXI_RD_BUS_SAFETY_ERR_STAT_CMD
0x18354 MSS_CTRL_R5SS0_CORE1_AXI_S_BUS_SAFETY_ERR_STAT_WRITE
  fields as MSS_CTRL_R5SS0_CORE0_AXI_RD_BUS_SAFETY_ERR_STAT_CMD
0x18358 MSS_CTRL_R5SS0_CORE1_AXI_S_BUS_SAFETY_ERR_STAT_READ
  fields as MSS_CTRL_R5SS0_CORE0_AXI_RD_BUS_SAFETY_ERR_STAT_CMD
0x1835C MSS_CTRL_R5SS0_CORE1_AXI_S_BUS_SAFETY_ERR_STAT_WRITERESP
  fields as MSS_CTRL_R5SS0_CORE0_AXI_RD_BUS_SAFETY_ERR_STAT_CMD
0x18360 MSS_CTRL_R5SS1_CORE0_AXI_S_BUS_SAFETY_CTRL 24-bit access per field reset 0x7
  fields as MSS_CTRL_R5SS0_CORE0_AXI_RD_BUS_SAFETY_CTRL
0x18364 MSS_CTRL_R5SS1_CORE0_AXI_S_BUS_SAFETY_FI rw
  fields as MSS_CTRL_R5SS0_CORE0_AXI_RD_BUS_SAFETY_FI
0x18368 MSS_CTRL_R5SS1_CORE0_AXI_S_BUS_SAFETY_ERR
  fields as MSS_CTRL_R5SS0_CORE0_AXI_RD_BUS_SAFETY_ERR
0x1836C MSS_CTRL_R5SS1_CORE0_AXI_S_BUS_SAFETY_ERR_STAT_DATA0 16-bit
  fields as MSS_CTRL_R5SS0_CORE0_AXI_RD_BUS_SAFETY_ERR_STAT_DATA0
0x18370 MSS_CTRL_R5SS1_CORE0_AXI_S_BUS_SAFETY_ERR_STAT_CMD
  fields as MSS_CTRL_R5SS0_CORE0_AXI_RD_BUS_SAFETY_ERR_STAT_CMD
0x18374 MSS_CTRL_R5SS1_CORE0_AXI_S_BUS_SAFETY_ERR_STAT_WRITE
  fields as MSS_CTRL_R5SS0_CORE0_AXI_RD_BUS_SAFETY_ERR_STAT_CMD
0x18378 MSS_CTRL_R5SS1_CORE0_AXI_S_BUS_SAFETY_ERR_STAT_READ
  fields as MSS_CTRL_R5SS0_CORE0_AXI_RD_BUS_SAFETY_ERR_STAT_CMD
0x1837C MSS_CTRL_R5SS1_CORE0_AXI_S_BUS_SAFETY_ERR_STAT_WRITERESP
  fields as MSS_CTRL_R5SS0_CORE0_AXI_RD_BUS_SAFETY_ERR_STAT_CMD
0x18380 MSS_CTRL_R5SS1_CORE1_AXI_S_BUS_SAFETY_CTRL 24-bit access per field reset 0x7
  fields as MSS_CTRL_R5SS0_CORE0_AXI_RD_BUS_SAFETY_CTRL
0x18384 MSS_CTRL_R5SS1_CORE1_AXI_S_BUS_SAFETY_FI rw
  fields as MSS_CTRL_R5SS0_CORE0_AXI_RD_BUS_SAFETY_FI
0x18388 MSS_CTRL_R5SS1_CORE1_AXI_S_BUS_SAFETY_ERR
  fields as MSS_CTRL_R5SS0_CORE0_AXI_RD_BUS_SAFETY_ERR
0x1838C MSS_CTRL_R5SS1_CORE1_AXI_S_BUS_SAFETY_ERR_STAT_DATA0 16-bit
  fields as MSS_CTRL_R5SS0_CORE0_AXI_RD_BUS_SAFETY_ERR_STAT_DATA0
0x18390 MSS_CTRL_R5SS1_CORE1_AXI_S_BUS_SAFETY_ERR_STAT_CMD
  fields as MSS_CTRL_R5SS0_CORE0_AXI_RD_BUS_SAFETY_ERR_STAT_CMD
0x18394 MSS_CTRL_R5SS1_CORE1_AXI_S_BUS_SAFETY_ERR_STAT_WRITE
  fields as MSS_CTRL_R5SS0_CORE0_AXI_RD_BUS_SAFETY_ERR_STAT_CMD
0x18398 MSS_CTRL_R5SS1_CORE1_AXI_S_BUS_SAFETY_ERR_STAT_READ
  fields as MSS_CTRL_R5SS0_CORE0_AXI_RD_BUS_SAFETY_ERR_STAT_CMD
0x1839C MSS_CTRL_R5SS1_CORE1_AXI_S_BUS_SAFETY_ERR_STAT_WRITERESP
  fields as MSS_CTRL_R5SS0_CORE0_AXI_RD_BUS_SAFETY_ERR_STAT_CMD
0x183A0 MSS_CTRL_TPTC00_RD_BUS_SAFETY_CTRL 24-bit access per field reset 0x7
  fields as MSS_CTRL_R5SS0_CORE0_AXI_RD_BUS_SAFETY_CTRL
0x183A4 MSS_CTRL_TPTC00_RD_BUS_SAFETY_FI rw
  fields as MSS_CTRL_R5SS0_CORE0_AXI_RD_BUS_SAFETY_FI
0x183A8 MSS_CTRL_TPTC00_RD_BUS_SAFETY_ERR
  fields as MSS_CTRL_R5SS0_CORE0_AXI_RD_BUS_SAFETY_ERR
